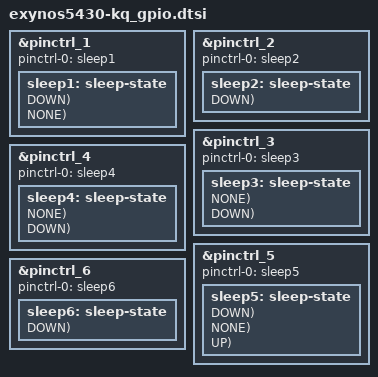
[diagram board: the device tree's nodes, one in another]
/*
 * SAMSUNG UNIVERSAL5430 board device tree source
 *
 * Copyright (c) 2014 Samsung Electronics Co., Ltd.
 *		http://www.samsung.com
 *
 * This program is free software; you can redistribute it and/or modify
 * it under the terms of the GNU General Public License version 2 as
 * published by the Free Software Foundation.
*/


#define PIN_PULL_NONE		0
#define PIN_PULL_DOWN		1
#define PIN_PULL_UP		3

#define PIN_DRV_LV1		0
#define PIN_DRV_LV2		2
#define PIN_DRV_LV3		1
#define PIN_DRV_LV4		3

#define PIN_PDN_OUT0		0
#define PIN_PDN_OUT1		1
#define PIN_PDN_INPUT		2
#define PIN_PDN_PREV		3

#define PIN_IN(_pin, _pull, _drv)			\
	_pin {						\
		samsung,pins = #_pin;			\
		samsung,pin-function = <0>;		\
		samsung,pin-pud = <PIN_PULL_ ##_pull>;	\
		samsung,pin-drv = <PIN_DRV_ ##_drv>;	\
	}

#define PIN_OUT(_pin, _drv)				\
	_pin {						\
		samsung,pins = #_pin;			\
		samsung,pin-function = <1>;		\
		samsung,pin-pud = <0>;			\
		samsung,pin-drv = <PIN_DRV_ ##_drv>;	\
	}

#define PIN_OUT_SET(_pin, _val, _drv)			\
	_pin {						\
		samsung,pins = #_pin;			\
		samsung,pin-function = <1>;		\
		samsung,pin-pud = <0>;			\
		samsung,pin-drv = <PIN_DRV_ ##_drv>;	\
		samsung,pin-val	= <_val>;		\
	}

#define PIN_SLP(_pin, _mode, _pull)				\
	_pin {							\
		samsung,pins = #_pin;				\
		samsung,pin-con-pdn = <PIN_PDN_ ##_mode>;	\
		samsung,pin-pud-pdn = <PIN_PULL_ ##_pull>;	\
	}

&pinctrl_1 {
	pinctrl-names = "sleep";
	pinctrl-0 = <&sleep1>;
	sleep1: sleep-state {
		PIN_SLP(gpz0-0, INPUT, DOWN);	/* MM_I2S_CLK */
		PIN_SLP(gpz0-1, INPUT, DOWN);	/* NC */
		PIN_SLP(gpz0-2, INPUT, DOWN);	/* MM_I2S_SYNC */
		PIN_SLP(gpz0-3, INPUT, DOWN);	/* MM_I2S_DI */
		PIN_SLP(gpz0-4, INPUT, DOWN);	/* MM_I2S_DO */
		PIN_SLP(gpz0-5, INPUT, DOWN);	/* NC */
		PIN_SLP(gpz0-6, INPUT, DOWN);	/* NC */

		PIN_SLP(gpz1-0, INPUT, DOWN);	/* BT_UART_TXD */
		PIN_SLP(gpz1-1, INPUT, NONE);	/* BT_UART_RXD */
		PIN_SLP(gpz1-2, INPUT, DOWN);	/* BT_UART_CTS */
		PIN_SLP(gpz1-3, INPUT, DOWN);	/* BT_UART_RTS */
	};
};

&pinctrl_2 {
	pinctrl-names = "sleep";
	pinctrl-0 = <&sleep2>;
	sleep2: sleep-state {
		PIN_SLP(gpv6-0, INPUT, DOWN);	/* NC */
		PIN_SLP(gpv6-1, INPUT, DOWN);	/* NC */
		PIN_SLP(gpv6-2, INPUT, DOWN);	/* NC */
	};
};

&pinctrl_3 {
	pinctrl-names = "sleep";
	pinctrl-0 = <&sleep3>;
	sleep3: sleep-state {
		PIN_SLP(gph1-0, INPUT, NONE);	/* 10K PU */
		PIN_SLP(gph1-1, INPUT, DOWN);	/* NC */
		PIN_SLP(gph1-2, INPUT, NONE);	/* 10K PU */
		PIN_SLP(gph1-3, INPUT, DOWN);	/* NC */

		PIN_SLP(gpr4-0, INPUT, DOWN);	/* T_FLASH_CLK */
		PIN_SLP(gpr4-1, INPUT, DOWN);	/* T_FLASH_CMD */
		PIN_SLP(gpr4-2, INPUT, DOWN);	/* NC */
		PIN_SLP(gpr4-3, INPUT, DOWN);	/* T_FLASH_D(0) */
		PIN_SLP(gpr4-4, INPUT, DOWN);	/* T_FLASH_D(1) */
		PIN_SLP(gpr4-5, INPUT, DOWN);	/* T_FLASH_D(2) */
		PIN_SLP(gpr4-6, INPUT, DOWN);	/* T_FLASH_D(3) */

		PIN_SLP(gpr0-0, INPUT, DOWN);	/* NAND_CLK */
		PIN_SLP(gpr0-1, INPUT, NONE);	/* NAND_CMD */
		PIN_SLP(gpr0-2, INPUT, DOWN);	/* NAND_RCLK */
		PIN_SLP(gpr0-3, INPUT, DOWN);	/* NC */
		PIN_SLP(gpr0-4, INPUT, DOWN);	/* NC */

		PIN_SLP(gpr1-0, INPUT, NONE);	/* NAND_D(0) */
		PIN_SLP(gpr1-1, INPUT, NONE);	/* NAND_D(1) */
		PIN_SLP(gpr1-2, INPUT, NONE);	/* NAND_D(2) */
		PIN_SLP(gpr1-3, INPUT, NONE);	/* NAND_D(3) */
		PIN_SLP(gpr1-4, INPUT, NONE);	/* NAND_D(4) */
		PIN_SLP(gpr1-5, INPUT, NONE);	/* NAND_D(5) */
		PIN_SLP(gpr1-6, INPUT, NONE);	/* NAND_D(6) */
		PIN_SLP(gpr1-7, INPUT, NONE);	/* NAND_D(7) */

		PIN_SLP(gpr2-0, INPUT, DOWN);	/* WLAN_SDIO_CLK */
		PIN_SLP(gpr2-1, INPUT, NONE);	/* WLAN_SDIO_CMD */

		PIN_SLP(gpr3-0, INPUT, NONE);	/* WLAN_SDIO_D(0) */
		PIN_SLP(gpr3-1, INPUT, NONE);	/* WLAN_SDIO_D(1) */
		PIN_SLP(gpr3-2, INPUT, NONE);	/* WLAN_SDIO_D(2) */
		PIN_SLP(gpr3-3, INPUT, NONE);	/* WLAN_SDIO_D(3) */
		PIN_SLP(gpr3-4, INPUT, DOWN);	/* NC */
		PIN_SLP(gpr3-5, INPUT, DOWN);	/* CAM_SENSOR_DET */
		PIN_SLP(gpr3-6, INPUT, DOWN);	/* NC */
		PIN_SLP(gpr3-7, INPUT, DOWN);	/* NC */
	};
};

&pinctrl_4 {
	pinctrl-names = "sleep";
	pinctrl-0 = <&sleep4>;
	sleep4: sleep-state {
		PIN_SLP(gpj0-0, INPUT, NONE);	/* NFC_I2C_SDA */
		PIN_SLP(gpj0-1, INPUT, NONE);	/* NFC_I2C_SCL */
		PIN_SLP(gpj0-2, INPUT, DOWN);	/* NFC_FIRMWARE */
	};
};

&pinctrl_5 {
	pinctrl-names = "sleep";
	pinctrl-0 = <&sleep5>;
	sleep5: sleep-state {
		PIN_SLP(gpv7-0, INPUT, DOWN);	/* MHL_RST */
		PIN_SLP(gpv7-1, INPUT, NONE);	/* CRESET_B */
		PIN_SLP(gpv7-2, PREV, NONE);	/* MLCD_RST */
		PIN_SLP(gpv7-3, PREV, NONE);	/* CODEC_RESET_N */
		PIN_SLP(gpv7-4, PREV, NONE);	/* MICBIAS_EN_AP */

		PIN_SLP(gpb0-0, INPUT, NONE);	/* FUEL_SDA_1.8V */
		PIN_SLP(gpb0-1, INPUT, NONE);	/* FUEL_SCL_1.8V */
		PIN_SLP(gpb0-2, INPUT, DOWN);	/* TOUCH_I2C_SDA */
		PIN_SLP(gpb0-3, INPUT, DOWN);	/* TOUCH_I2C_SCL */
		PIN_SLP(gpb0-4, INPUT, DOWN);	/* ERR_FG */

		PIN_SLP(gpc0-0, INPUT, DOWN);	/* VT_CAM_STBY */
		PIN_SLP(gpc0-1, INPUT, DOWN);	/* FLASH_LED_STROBE */
		PIN_SLP(gpc0-2, INPUT, DOWN);	/* FLASH_LED_TORCH */
		PIN_SLP(gpc0-3, INPUT, DOWN);	/* VT_CAM_NRST */
		PIN_SLP(gpc0-4, INPUT, DOWN);	/* MAIN_CAM_RST */
		PIN_SLP(gpc0-5, INPUT, DOWN);	/* FLASH_FLINH */
		PIN_SLP(gpc0-6, INPUT, DOWN);	/* FROM_SPI_SSN */
		PIN_SLP(gpc0-7, INPUT, DOWN);	/* NC */

		PIN_SLP(gpc1-0, INPUT, DOWN);	/* COMP_SPI_INT */
		PIN_SLP(gpc1-1, INPUT, DOWN);	/* NC */

		PIN_SLP(gpc2-0, INPUT, DOWN);	/* MAIN_CAM_SDA */
		PIN_SLP(gpc2-1, INPUT, DOWN);	/* MAIN_CAM_SCL */
		PIN_SLP(gpc2-2, INPUT, DOWN);	/* AF_SDA */
		PIN_SLP(gpc2-3, INPUT, DOWN);	/* AF_SCL */
		PIN_SLP(gpc2-4, INPUT, DOWN);	/* VT_CAM_SDA */
		PIN_SLP(gpc2-5, INPUT, DOWN);	/* VT_CAM_SCL */

		PIN_SLP(gpc3-0, INPUT, DOWN);	/* COMP_FROM_SPI_SCLK */
		PIN_SLP(gpc3-1, INPUT, DOWN);	/* COMP_SPI_SSN */
		PIN_SLP(gpc3-2, INPUT, DOWN);	/* COMP_FROM_SPI_MISO */
		PIN_SLP(gpc3-3, INPUT, DOWN);	/* COMP_FROM_SPI_MOSI */
		PIN_SLP(gpc3-4, INPUT, DOWN);	/* NC */
		PIN_SLP(gpc3-5, INPUT, DOWN);	/* NC */
		PIN_SLP(gpc3-6, INPUT, DOWN);	/* NC */
		PIN_SLP(gpc3-7, INPUT, DOWN);	/* NC */

		PIN_SLP(gpg0-0, INPUT, DOWN);	/* NC */
		PIN_SLP(gpg0-1, INPUT, DOWN);	/* LCD_TE */

		PIN_SLP(gpd0-0, INPUT, DOWN);	/* NC */
		PIN_SLP(gpd0-1, INPUT, DOWN);	/* NC */
		PIN_SLP(gpd0-2, INPUT, DOWN);	/* NC */
		PIN_SLP(gpd0-3, INPUT, DOWN);	/* NC */

		PIN_SLP(gpd1-0, INPUT, DOWN);	/* UART_RXD */
		PIN_SLP(gpd1-1, INPUT, DOWN);	/* UART_TXD */
		PIN_SLP(gpd1-2, INPUT, NONE);	/* COMP_I2C_SDA */
		PIN_SLP(gpd1-3, INPUT, NONE);	/* COMP_I2C_SCL */
		PIN_SLP(gpd1-4, INPUT, DOWN);	/* HEALTH_UART_RXD */
		PIN_SLP(gpd1-5, INPUT, DOWN);	/* HEALTH_UART_TXD */

		PIN_SLP(gpd2-0, INPUT, NONE);	/* AP_PMIC_SDA */
		PIN_SLP(gpd2-1, INPUT, NONE);	/* AP_PMIC_SCL */
		PIN_SLP(gpd2-2, INPUT, NONE);	/* MEM_LDO_SDA */
		PIN_SLP(gpd2-3, INPUT, NONE);	/* MEM_LDO_SCL */
		PIN_SLP(gpd2-4, INPUT, DOWN);	/* VIB_PWM */
		PIN_SLP(gpd2-5, INPUT, NONE);	/* COVER_ID */
		PIN_SLP(gpd2-6, INPUT, DOWN);	/* MHLC_I2C_SDA */
		PIN_SLP(gpd2-7, INPUT, DOWN);	/* MHLC_I2C_SCL */

		PIN_SLP(gpd4-0, INPUT, NONE);	/* MCU_nRST_1.8V */
		PIN_SLP(gpd4-1, INPUT, DOWN);	/* HEALTH_3.3V_EN  */
		PIN_SLP(gpd4-2, INPUT, DOWN);	/* FPGA_SPI_EN */
		PIN_SLP(gpd4-3, INPUT, NONE);	/* FLASH_LED_DUAL_SDA */
		PIN_SLP(gpd4-4, INPUT, NONE);	/* FLASH_LED_DUAL_SCL */

		PIN_SLP(gpd5-0, INPUT, DOWN);	/* BTP_SPI_CLK */
		PIN_SLP(gpd5-1, INPUT, DOWN);	/* BTP_SPI_CS_N */
		PIN_SLP(gpd5-2, INPUT, DOWN);	/* BTP_SPI_MISO */
		PIN_SLP(gpd5-3, INPUT, DOWN);	/* BTP_SPI_MOSI */

		PIN_SLP(gpd8-0, INPUT, NONE);	/* SHUB_SPI_SCK */
		PIN_SLP(gpd8-1, INPUT, NONE);	/* SHUB_SPI_SSN */

		PIN_SLP(gpd6-0, INPUT, NONE);	/* SHUB_SPI_MISO */
		PIN_SLP(gpd6-1, INPUT, NONE);	/* SHUB_SPI_MOSI */
		PIN_SLP(gpd6-2, OUT0, NONE);	/* CODEC_SPI_SCK */
		PIN_SLP(gpd6-3, OUT0, NONE);	/* CODEC_SPI_SS_N */
		PIN_SLP(gpd6-4, INPUT, DOWN);	/* CODEC_SPI_MISO */
		PIN_SLP(gpd6-5, OUT0, NONE);	/* CODEC_SPI_MOSI */

		PIN_SLP(gpd7-0, OUT0, DOWN);	/* MAIN_CAM_MCLK */
		PIN_SLP(gpd7-1, INPUT, DOWN);	/* COMPANION_MCLK */
		PIN_SLP(gpd7-2, OUT0, DOWN);	/* VT_CAM_MCLK */

		PIN_SLP(gpf0-0, PREV, NONE);	/* CODEC_LDO_EN */
		PIN_SLP(gpf0-1, INPUT, NONE);	/* CDONE */
		PIN_SLP(gpf0-2, INPUT, DOWN);	/* MHL_INT */
		PIN_SLP(gpf0-3, INPUT, DOWN);	/* OCP_FLAG */
		PIN_SLP(gpf0-4, INPUT, DOWN);	/* IRDA_IRQ */
		PIN_SLP(gpf0-5, INPUT, DOWN);	/* NC */
		PIN_SLP(gpf0-6, INPUT, DOWN);	/* NC */
		PIN_SLP(gpf0-7, INPUT, NONE);	/* CCI_MODE */

		PIN_SLP(gpf1-0, INPUT, DOWN);	/* NC */
		PIN_SLP(gpf1-1, INPUT, DOWN);	/* NC */
		PIN_SLP(gpf1-2, INPUT, DOWN);	/* NC */
		PIN_SLP(gpf1-3, INPUT, DOWN);	/* LCD_TE */
		PIN_SLP(gpf1-4, INPUT, DOWN);	/* NFC_EN */
		PIN_SLP(gpf1-5, PREV, NONE);	/* LCD_1.5V_EN */
		PIN_SLP(gpf1-6, INPUT, DOWN);	/* NC */
		PIN_SLP(gpf1-7, INPUT, DOWN);	/* CAM_OIS_EN */

		PIN_SLP(gpf2-0, INPUT, DOWN);	/* TSP_ID */
		PIN_SLP(gpf2-1, INPUT, DOWN);	/* OCTA_ID */
		PIN_SLP(gpf2-2, INPUT, DOWN);	/* NC */
		PIN_SLP(gpf2-3, INPUT, DOWN);	/* CAM_DOUBLE_KEY1 */

		PIN_SLP(gpf3-0, INPUT, DOWN);	/* CAM_DOUBLE_KEY2 */
		PIN_SLP(gpf3-1, INPUT, DOWN);	/* CAM_DOUBLE_KEY3 */
		PIN_SLP(gpf3-2, INPUT, DOWN);	/* USB3.0_REDRIVER_EN */
		PIN_SLP(gpf3-3, INPUT, DOWN);	/* NC */
		PIN_SLP(gpf3-4, OUT0, NONE);	/* LDO17_EN */
		PIN_SLP(gpf3-5, PREV, NONE);	/* BOOT_LDO */

		PIN_SLP(gpf4-0, PREV, NONE);	/* BTP_LDO_EN */
		PIN_SLP(gpf4-1, INPUT, DOWN);	/* NC */
		PIN_SLP(gpf4-2, INPUT, DOWN);	/* NC */
		PIN_SLP(gpf4-3, PREV, NONE);	/* AP2MDM_STATUS */
		PIN_SLP(gpf4-4, PREV, NONE);	/* AP2MDM_ERR_FATAL */
		PIN_SLP(gpf4-5, INPUT, DOWN);	/* AP2MDM_VDDMIN */
		PIN_SLP(gpf4-6, INPUT, DOWN);	/* NC */
		PIN_SLP(gpf4-7, PREV, NONE);	/* AP2MDM_PON_RESET_N */

		PIN_SLP(gpf5-0, PREV, NONE);	/* AP2MDM_HSIC_PORT_ACTIVE */
		PIN_SLP(gpf5-1, INPUT, DOWN);	/* NC */
		PIN_SLP(gpf5-2, INPUT, DOWN);	/* NC */
		PIN_SLP(gpf5-3, INPUT, DOWN);	/* NC */
		PIN_SLP(gpf5-4, INPUT, UP);	/* WRSTB_IN */
		PIN_SLP(gpf5-5, INPUT, DOWN);	/* NC */
		PIN_SLP(gpf5-6, INPUT, DOWN);	/* NC */
		PIN_SLP(gpf5-7, INPUT, DOWN);	/* COMPANION_RSSTN */

		PIN_SLP(gpg1-0, PREV, NONE);	/* AP2MDM_PMIC_RESET_N */
		PIN_SLP(gpg1-1, INPUT, DOWN);	/* NC */
		PIN_SLP(gpg1-2, INPUT, DOWN);	/* COMP_EN */
		PIN_SLP(gpg1-3, INPUT, DOWN);	/* SIM_SLOT */
		PIN_SLP(gpg1-4, PREV, NONE);	/* BT_EN */

		PIN_SLP(gpg2-0, PREV, NONE);	/* WLAN_EN */
		PIN_SLP(gpg2-1, INPUT, DOWN);	/* VT_CAM_ID */
		PIN_SLP(gpg2-2, INPUT, NONE);	/* FPGA_SPI_SI */
		PIN_SLP(gpg2-3, INPUT, NONE);	/* FPGA_SPI_CLK */
		PIN_SLP(gpg2-4, INPUT, DOWN);	/* AP2MDM_HSIC_RDY */

		PIN_SLP(gpg3-0, INPUT, NONE);	/* IF_PMIC_SDA_1.8V */
		PIN_SLP(gpg3-1, INPUT, NONE);	/* IF_PMIC_SCL_1.8V */
		PIN_SLP(gpg3-2, INPUT, DOWN);	/* MHL_I2C_SDA */
		PIN_SLP(gpg3-3, INPUT, DOWN);	/* MHL_I2C_SCL */
		PIN_SLP(gpg3-4, INPUT, NONE);	/* HW_REV0 */
		PIN_SLP(gpg3-5, INPUT, NONE);	/* HW_REV1 */
		PIN_SLP(gpg3-6, INPUT, NONE);	/* HW_REV2 */
		PIN_SLP(gpg3-7, INPUT, NONE);	/* HW_REV3 */
	};
};

&pinctrl_6 {
	pinctrl-names = "sleep";
	pinctrl-0 = <&sleep6>;
	sleep6: sleep-state {
		PIN_SLP(gpj1-0, INPUT, DOWN);	/* TS_I2C_SDA */
		PIN_SLP(gpj1-1, INPUT, DOWN);	/* TS_I2C_SCL */
		PIN_SLP(gpj1-2, INPUT, DOWN);	/* NC */
	};
};
